# M55M1 register map
File version: 1.0
Registers are 32-bit, read-write, reset 0x0 unless marked. A register's access mark holds for its fields unless they carry their own. Offsets are from the block's base; [hi:lo] are bit positions; {n}, {i} and the like mark numbered series; 'fields as' and 'values as' point back to an identical list.

## CCAP — CCAP Register Map
Base 0x40401000
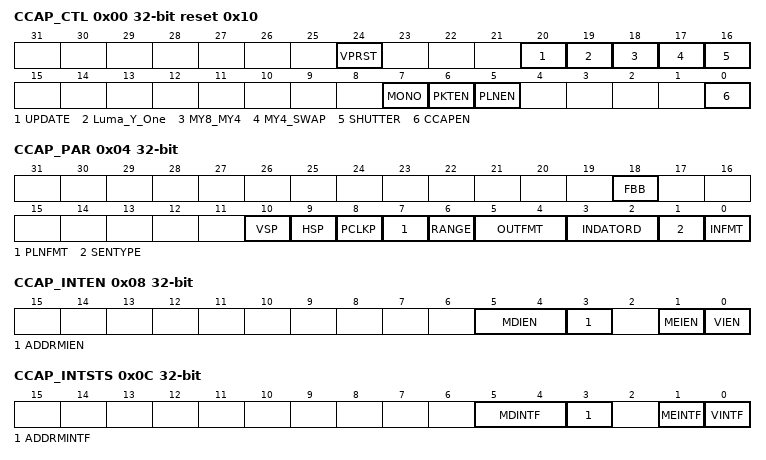
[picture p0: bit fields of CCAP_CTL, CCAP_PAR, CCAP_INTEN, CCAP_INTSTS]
0x00 CCAP_CTL reset 0x10 — Camera Capture Interface Control Register
  [24] VPRST — Capture Interface Reset. Note: Please use VPRST only when CCAPEN is 0.
    0=Capture interface reset Disabled; 1=Capture interface reset Enabled
  [20] UPDATE — Update Register at New Frame
    0=Update register at new frame Disabled; 1=Update register at new frame Enabled (auto cleared to 0 when register updated)
  [19] Luma_Y_One — Color/Monochrome CMOS Sensor Luminance 8-bit Y to 1-bit Y Conversion. Note: Color CMOS sensor U/V components are ignored when the Luma_Y_One is enabled.
    0=Color/Monochrome CMOS sensor Luma-Y-One bit Disabled; 1=Color/Monochrome CMOS sensor Luma-Y-One bit Enabled
  [18] MY8_MY4 — Monochrome CMOS Sensor Data I/O Interface
    0=Monochrome CMOS sensor is by the 4-bit data I/O interface; 1=Monochrome CMOS sensor is by the 8-bit data I/O interface
  [17] MY4_SWAP — Monochrome CMOS Sensor 4-bit Data Nibble Swap
    0=The 4-bit data input sequence: 1st Pixel is for 1st Nibble (1st pixel @MSB); 1=The 4-bit data input sequence: 1st Pixel is for 2nd Nibble (1st pixel @LSB)
  [16] SHUTTER — Camera Capture Interface Automatically Disable the Capture Interface After a Frame Had Been Captured
    0=Shutter Disabled; 1=Shutter Enabled
  [7] MONO — Monochrome CMOS Sensor Select
    0=Color CMOS Sensor; 1=Monochrome CMOS Sensor. The U/V components are ignored when the MONO is enabled
  [6] PKTEN — Packet Output Enable Bit
    0=Packet output Disabled; 1=Packet output Enabled
  [5] PLNEN — Planar Output Enable Bit
    0=Planar output Disabled; 1=Planar output Enabled
  [0] CCAPEN — Camera Capture Interface Enable Bit
    0=Camera Capture Interface Disabled; 1=Camera Capture Interface Enabled
0x04 CCAP_PAR — Camera Capture Interface Parameter Register
  [18] FBB — Field by Blank. Field by Blank (only in ccir-656 mode) means blanking pixel data(0x80108010) have to transfer to system memory or not.
    0=Field by blank Disabled. (blank pixel data will transfer to system memory); 1=Field by blank Enabled. (only active data will transfer to system memory)
  [10] VSP — Sensor Vsync Polarity
    0=Sync Low; 1=Sync High
  [9] HSP — Sensor Hsync Polarity
    0=Sync Low; 1=Sync High
  [8] PCLKP — Sensor Pixel Clock Polarity
    0=Input video data and signals are latched by falling edge of Pixel Clock; 1=Input video data and signals are latched by rising edge of Pixel Clock
  [7] PLNFMT — Planar Output YUV Format
    0=YUV422; 1=YUV420
  [6] RANGE — Scale Input YUV CCIR601 Color Range to Full Range
    0=Default; 1=Scale to full range
  [5:4] OUTFMT — Image Data Format Output to System Memory
    0=YCbCr422. RGB888 or ARGB8888 with UINT8. RGB888 or ARGB8888 with INT8; 1=Only output Y. (Select this format when CCAP_CTL 'Luma_Y_One' or 'MONO' enabled); 2=RGB555; 3=RGB565
  [3:2] INDATORD — Sensor Input Data Order
    0=Sensor input data (Byte 0 1 2 3) is Y0 U0 Y1 V0. Sensor input data (Byte 0) is {R[4:0],G[5:3]}. Sensor input data (Byte 0, Byte 1, Byte 2) is R[7:0], G[7:0], B[7:0]. Sensor input data (Byte 0, Byte 1, Byte 2) is B[7:0], R[7:0], G[7:0]; 1=Sensor input data (Byte 0 1 2 3) is Y0 V0 Y1 U0. Sensor input data (Byte 0) is {B[4:0],G[5:3]}. Sensor input data (Byte 0, Byte 1, Byte 2) is R[7:0], B[7:0], G[7:0]. Sensor input data (Byte 0, Byte 1, Byte 2) is B[7:0], G[7:0], R[7:0]; 2=Sensor input data (Byte 0 1 2 3) is U0 Y0 V0 Y1. Sensor input data (Byte 0) is {G[2:0],B[4:0]}. Sensor input data (Byte 0, Byte 1, Byte 2) is G[7:0], R[7:0], B[7:0]. Reserved; 3=Sensor input data (Byte 0 1 2 3) is V0 Y0 U0 Y1. Sensor input data (Byte 0) is {G[2:0],R[4:0]}. Sensor input data (Byte 0, Byte 1, Byte 2) is G[7:0], B[7:0], R[7:0]. Reserved
  [1] SENTYPE — Sensor Input Type
    0=CCIR601; 1=CCIR656, Vsync Hsync embedded in the data signal
  [0] INFMT — Sensor Input Data Format
    0=YCbCr422; 1=RGB565. RGB888
0x08 CCAP_INTEN — Camera Capture Interface Interrupt Enable Register
  [5:4] MDIEN — Motion Detection Modes Interrupt Enable Bit
    0=Motion detection engine Disabled; 1=Only Motion detection Mode 1 interrupt Enabled; 2=Only Motion detection Mode 2 interrupt Enabled; 3=Both Motion detection Mode 1 and Mode 2 interrupt Enabled
  [3] ADDRMIEN — Address Match Interrupt Enable Bit
    0=Address match interrupt Disabled; 1=Address match interrupt Enabled
  [1] MEIEN — Bus Master Transfer Error Interrupt Enable Bit
    0=Bus Master Transfer error interrupt Disabled; 1=Bus Master Transfer error interrupt Enabled
  [0] VIEN — Video Frame End Interrupt Enable Bit
    0=Video frame end interrupt Disabled; 1=Video frame end interrupt Enabled
0x0C CCAP_INTSTS — Camera Capture Interface Interrupt Status Register
  [5:4] MDINTF — Motion Detection Modes Interrupt. Note: These two bits are cleared by writing 1 to them. Note: When Motion Detection Total SAD (Sum of Absolute Differences) Register (CCAP_MDTSAD) is larger than Motion Detection Total Threshold Register (CCAP_MDTTH), CCAP will trigger Motion detection Mode 1 interrupt. Note: When Motion Detection Window Overflow Counter Register (CCAP_MDWOC) is larger than Motion Detection Window Overflow Counter Threshold Register (CCAP_MDWOCTH), CCAP will trigger Motion detection Mode 2 interrupt.
    0=Motion detection Mode 1 and Mode 2 interrupt did not occur; 1=Only Motion detection Mode 1 interrupt occured; 2=Only Motion detection Mode 2 interrupt occured; 3=Both Motion detection Mode 1 and Mode 2 interrupt occured
  [3] ADDRMINTF — Memory Address Match Interrupt. Note: This bit is cleared by writing 1 to it.
    0=Memory Address Match Interrupt did not occur; 1=Memory Address Match Interrupt occurred
  [1] MEINTF — Bus Master Transfer Error Interrupt. Note: This bit is cleared by writing 1 to it.
    0=Transfer Error did not occur; 1=Transfer Error occurred
  [0] VINTF — Video Frame End Interrupt. Note: This bit is cleared by writing 1 to it.
    0=Did not receive a frame completely; 1=Received a frame completely
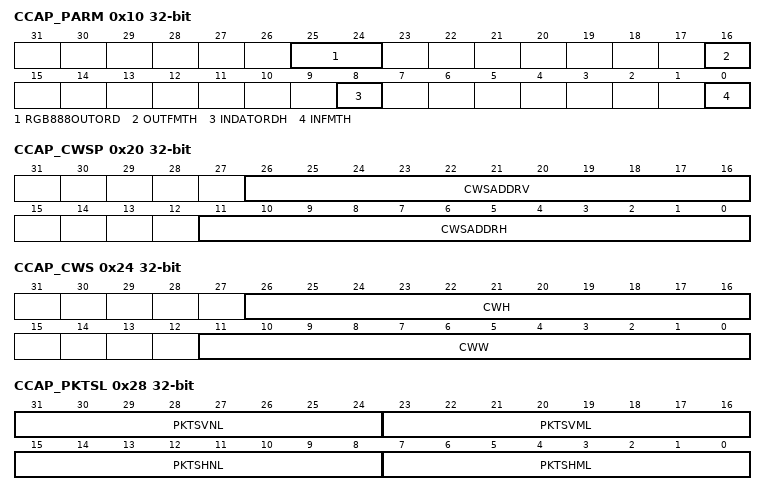
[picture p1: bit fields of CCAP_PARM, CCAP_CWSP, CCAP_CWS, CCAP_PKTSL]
0x10 CCAP_PARM — Camera Capture Interface Parameter Register (MSB)
  [25:24] RGB888OUTORD — Sensor RGB888 Output Data Order
    0=Sensor output data (Byte 0 1 2) is B, G, R loop for RGB888; 1=Sensor output data (Byte 0 1 2) is R, G, B loop for RGB888; 2=Sensor output data (Byte 0 1 2 3) is B, G, R, 0xFF loop for ARGB8888; 3=Sensor output data (Byte 0 1 2 3) is 0xFF, R, G, B loop for ARGB8888
  [16] OUTFMTH — Image Data Format Output to System Memory. Specify the higher 1-bit of of OUTFMT(CCAP_PAR[5:4]). Please refer to the register'CCAP_PAR' to check the cooperation between these two registers.
  [8] INDATORDH — Sensor Input Data Order. Specify the higher 1-bit of of INDATORD (CCAP_PAR[3:2]). Please refer to the register'CCAP_PAR' to check the cooperation between these two registers.
  [0] INFMTH — Sensor Input Data Format. Specify the higher 1-bit of of INFMT (CCAP_PAR[0]). Please refer to the register'CCAP_PAR' to check the cooperation between these two registers.
0x20 CCAP_CWSP — Cropping Window Starting Address Register
  [26:16] CWSADDRV — Cropping Window Vertical Starting Address. Specify the value of the cropping window vertical start address.
  [11:0] CWSADDRH — Cropping Window Horizontal Starting Address. Specify the value of the cropping window horizontal start address.
0x24 CCAP_CWS — Cropping Window Size Register
  [26:16] CWH — Cropping Window Height. Specify the size of the cropping window height.
  [11:0] CWW — Cropping Window Width. Specify the size of the cropping window width.
0x28 CCAP_PKTSL — Packet Scaling Vertical/Horizontal Factor Register (LSB)
  [31:24] PKTSVNL — Packet Scaling Vertical Factor N. Specify the lower 8-bit of numerator part (N) of the vertical scaling factor. The lower 8-bit will be cascaded with higher 8-bit (PKDSVNH) to form a 16-bit numerator of vertical factor.
  [23:16] PKTSVML — Packet Scaling Vertical Factor M. Specify the lower 8-bit of denominator part (M) of the vertical scaling factor. The lower 8-bit will be cascaded with higher 8-bit (PKDSVMH) to form a 16-bit denominator (M) of vertical factor. The output image width will be equal to the image height * N/M. Note: The value of N must be equal to or less than M.
  [15:8] PKTSHNL — Packet Scaling Horizontal Factor N. Specify the lower 8-bit of numerator part (N) of the horizontal scaling factor. The lower 8-bit will be cascaded with higher 8-bit (PKDSHNH) to form a 16-bit numerator of horizontal factor.
  [7:0] PKTSHML — Packet Scaling Horizontal Factor M. Specify the lower 8-bit of denominator part (M) of the horizontal scaling factor. The lower 8-bit will be cascaded with higher 8-bit (PKDSHMH) to form a 16-bit denominator (M) of vertical factor. The output image width will be equal to the image width * N/M. Note: The value of N must be equal to or less than M.
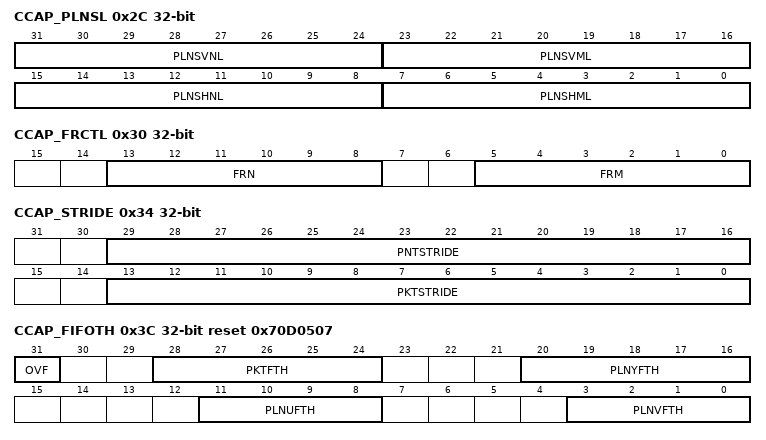
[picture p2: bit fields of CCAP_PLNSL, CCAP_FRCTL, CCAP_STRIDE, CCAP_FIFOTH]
0x2C CCAP_PLNSL — Planar Scaling Vertical/Horizontal Factor Register (LSB)
  [31:24] PLNSVNL — Planar Scaling Vertical Factor N. Specify the lower 8-bit of numerator part (N) of the vertical scaling factor. The lower 8-bit will be cascaded with higher 8-bit (PNDSVNH) to form a 16-bit numerator of vertical factor.
  [23:16] PLNSVML — Planar Scaling Vertical Factor M. Specify the lower 8-bit of denominator part (M) of the vertical scaling factor. The lower 8-bit will be cascaded with higher 8-bit (PNDSVMH) to form a 16-bit denominator (M) of vertical factor. The output image width will be equal to the image height * N/M. Note: The value of N must be equal to or less than M.
  [15:8] PLNSHNL — Planar Scaling Horizontal Factor N. Specify the lower 8-bit of numerator part (N) of the horizontal scaling factor. The lower 8-bit will be cascaded with higher 8-bit (PNDSHNH) to form a 16-bit numerator of horizontal factor.
  [7:0] PLNSHML — Planar Scaling Horizontal Factor M. Specify the lower 8-bit of denominator part (M) of the horizontal scaling factor. The lower 8-bit will be cascaded with higher 8-bit (PNDSHMH) to form a 16-bit denominator (M) of vertical factor. The output image width will be equal to the image width * N/M. Note: The value of N must be equal to or less than M.
0x30 CCAP_FRCTL — Scaling Frame Rate Factor Register
  [13:8] FRN — Scaling Frame Rate Factor N. Specify the numerator part (N) of the frame rate scaling factor.
  [5:0] FRM — Scaling Frame Rate Factor M. Specify the denominator part (M) of the frame rate scaling factor. The output image frame rate will be equal to input image frame rate * (N/M). Note: The value of N must be equal to or less than M.
0x34 CCAP_STRIDE — Frame Output Pixel Stride Width Register
  [29:16] PNTSTRIDE — Planar Frame Output Pixel Stride Width. The output pixel stride size of the planar pipe. It is a 32-pixel aligned stride width for the Luma-Y-One bit format or a 4-pixel aligned stride with for the Luma-Y-Eight bit format when color or monochrome CMOS sensors used. This means that every new captured line address is word alignment when color or monochrome CMOS sensors used.
  [13:0] PKTSTRIDE — Packet Frame Output Pixel Stride Width. The output pixel stride size of the packet pipe. It is a 32-pixel aligned stride width for the Luma-Y-One bit format or a 4-pixel aligned stride with for the Luma-Y-Eight bit format when color or monochrome CMOS sensors used. This means that every new captured line is by word alignment address when color or monochrome CMOS sensors used.
0x3C CCAP_FIFOTH reset 0x70D0507 — FIFO Threshold Register
  [31] OVF — FIFO Overflow Flag. Indicate the FIFO overflow flag.
  [28:24] PKTFTH — Packet FIFO Threshold. Specify the 5-bit value of the packet FIFO threshold.
  [20:16] PLNYFTH — Planar Y FIFO Threshold. Specify the 5-bit value of the planar Y FIFO threshold.
  [11:8] PLNUFTH — Planar U FIFO Threshold. Specify the 4-bit value of the planar U FIFO threshold.
  [3:0] PLNVFTH — Planar V FIFO Threshold. Specify the 4-bit value of the planar V FIFO threshold.
0x40 CCAP_CMPADDR reset 0xFFFFFFFC — Compare Memory Base Address Register
  [31:0] CMPADDR — Compare Memory Base Address. It is a word alignment address, that is, the address is aligned by ignoring the 2 LSB bits [1:0].
0x44 CCAP_LUMA_Y1_THD reset 0x80 — Luminance Y8 to Y1 Threshold Value Register
  [7:0] LUMA_Y1_THRESH — Luminance Y8 to Y1 Threshold Value. Specify the 8-bit threshold value for the luminance Y bit-8 to the luminance Y 1-bit conversion.
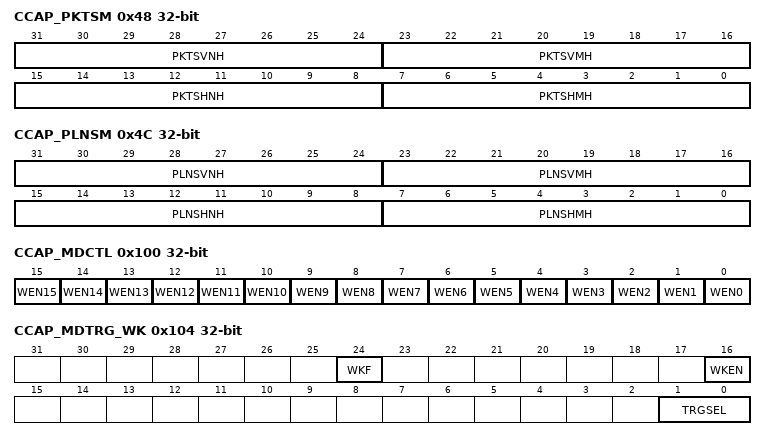
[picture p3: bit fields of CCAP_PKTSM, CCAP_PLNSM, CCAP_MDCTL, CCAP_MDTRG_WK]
0x48 CCAP_PKTSM — Packet Scaling Vertical/Horizontal Factor Register (MSB)
  [31:24] PKTSVNH — Packet Scaling Vertical Factor N. Specify the higher 8-bit of numerator part (N) of the vertical scaling factor. Please refer to the register 'CCAP_PKTSL' to check the cooperation between these two registers.
  [23:16] PKTSVMH — Packet Scaling Vertical Factor M. Specify the higher 8-bit of denominator part (M) of the vertical scaling factor. Please refer to the register 'CCAP_PKTSL' to check the cooperation between these two registers.
  [15:8] PKTSHNH — Packet Scaling Horizontal Factor N. Specify the higher 8-bit of numerator part (N) of the horizontal scaling factor. Please refer to the register 'CCAP_PKTSL' for the detailed operation.
  [7:0] PKTSHMH — Packet Scaling Horizontal Factor M. Specify the higher 8-bit of denominator part (M) of the horizontal scaling factor. Please refer to the register 'CCAP_PKTSL' for the detailed operation.
0x4C CCAP_PLNSM — Planar Scaling Vertical/Horizontal Factor Register (MSB)
  [31:24] PLNSVNH — Planar Scaling Vertical Factor N. Specifies the higher 8-bit of numerator part (N) of the vertical scaling factor. For detailed programming, please refer to the register 'CAP_PLNSL'.
  [23:16] PLNSVMH — Planar Scaling Vertical Factor M. Specifies the lower 8-bit of denominator part (M) of the vertical scaling factor. For detailed programming, please refer to the register 'CAP_PLNSL'.
  [15:8] PLNSHNH — Planar Scaling Horizontal Factor N. Specifies the higher 8-bit of numerator part (N) of the horizontal scaling factor. For detailed programming, please refer to the register 'CAP_PLNSL'.
  [7:0] PLNSHMH — Planar Scaling Horizontal Factor M. Specifies the higher 8-bit of denominator part (M) of the horizontal scaling factor. For detailed programming, please refer to the register 'CAP_PLNSL'.
0x50 CCAP_CURADDRP ro — Current Packet System Memory Address Byte Counter Register
  [31:0] CURADDR — Current Packet Output Memory Address Byte Counter
0x54 CCAP_CURADDRY ro — Current Planar Y System Memory Address Register
  [31:0] CURADDR — Current Planar Y Output Memory Address. Specify the 32-bit value of the current planar Y output memory address.
0x58 CCAP_CURADDRU ro — Current Planar U System Memory Address Register
  [31:0] CURADDR — Current Planar U Output Memory Address. Specify the 32-bit value of the current planar U output memory address.
0x5C CCAP_CURADDRV ro — Current Planar V System Memory Address Register
  [31:0] CURADDR — Current Planar V Output Memory Address. Specify the 32-bit value of the current planar V output memory address.
0x60 CCAP_PKTBA0 — System Memory Packet Base Address 0 Register
  [31:0] BASEADDR — System Memory Packet Base Address 0. It is a word alignment address, that is, the address is aligned by ignoring the 2 LSB bits [1:0].
0x80 CCAP_YBA — System Memory Planar Y Base Address Register
  [31:0] BASEADDR — System Memory Planar Y Base Address. It is a word alignment address, that is, the address is aligned by ignoring the 2 LSB bits [1:0].
0x84 CCAP_UBA — System Memory Planar U Base Address Register
  [31:0] BASEADDR — System Memory Planar U Base Address. It is a word alignment address, that is, the address is aligned by ignoring the 2 LSB bits [1:0].
0x88 CCAP_VBA — System Memory Planar V Base Address Register
  [31:0] BASEADDR — System Memory Planar V Base Address. It is a word alignment address, that is, the address is aligned by ignoring the 2 LSB bits [1:0].
0x100 CCAP_MDCTL — Motion Detection Control Register
  [n] WEN{n} (n=9..15) — Motion Detection Window {n} Enable Bit
    0=Motion Detection Window {n} Disabled; 1=Motion Detection Window {n} Enabled only when CCAP_INTEN[5:4] (MDIEN) is not equal to 0x0
  [8] WEN8 — Motion Detection Window 8 Enable Bit
    0=Motion Detection Window 8 Disabled; 1=Motion Detection Window 8 Enabled only when CCAP_INTEN[5:4] (MDIEN) is not equal to 0x0,
  [n] WEN{n} (n=0..7) — Motion Detection Window {n} Enable Bit
    values as WEN9
0x104 CCAP_MDTRG_WK — Motion Detection Trigger and Wakeup Register
  [24] WKF — CCAP Wake-up Flag. This bit indicates the interrupt wake-up flag status of CCAP. Note: This bit is cleared by writing 1 to it.
    0=CCAP does not cause CPU wake-up; 1=CPU wake-up from Idle or Power-down mode if MDINTF (CCAP_INTSTS[5:4]) are generated
  [16] WKEN — Wake-up Function Enable Bit. If this bit is set to 1, while Motion Detection Modes interrupt MDINTF (CCAP_INTSTS[5:4]) is 1 and MDIEN (CCAP_INTEN[5:4]) is enabled, the CCAP interrupt signal will generate a wake-up trigger event to CPU.
    0=Wake-up function Disabled if CCAP interrupt signal generated; 1=Wake-up function Enabled if CCAP interrupt signal generated
  [1:0] TRGSEL — Trigger Source Selection
    0=LPTMR0; 1=LPTMR1; 2=TTMR0; 3=TTMR1
0x110 CCAP_MDTTH — Motion Detection Total Threshold Register
  [20:0] MDTTH — Motion Detection Total Threshold. Specify the 21-bit threshold value for checking if the total SAD of all windows (CCAP_MDTSAD) is overflow. Note: The maximum value of MDTSAD is 0x12AD40.
0x114 CCAP_MDTSAD ro — Motion Detection Total SAD Register
  [20:0] MDTSAD — Motion Detection Total SAD. Note: The maximum value of MDTSAD is 0x12AD40.
0x120 CCAP_MDWOCTH — Motion Detection Window Overflow Counter Threshold Register
  [3:0] MDWOCTH — Motion Detection Window Overflow Counter threshold. Specify the 4-bit threshold value for checking if CCAP_MDWOC is overflow.
0x124 CCAP_MDWOC ro — Motion Detection Window Overflow Counter Register
  [4:0] MDWOC — Motion Detection Window Overflow Counter. The counter of windows that their CCAP_MDWSADx are larger than their CCAP_MDWTHx.
{0x140+4i} CCAP_MDWTH{i} (i=0..15) — Motion Detection Window Threshold {i} Register
  [16:0] MDWTH — Motion Detection Window Threshold. Specify the 17-bit threshold value for checking if the SAD of window x (CCAP_MDWSADx) is overflow. Note: The maximum value of MDWSAD is 0x12AD4.
{0x180+4i} CCAP_MDWSAD{i} ro (i=0..15) — Motion Detection Window SAD {i} Register
  [16:0] MDWSAD — Motion Detection Window SAD. The 17-bit value for the SAD (Sum of Absolute Differences) of window x. Note: The maximum value of MDWSAD is 0x12AD4.
